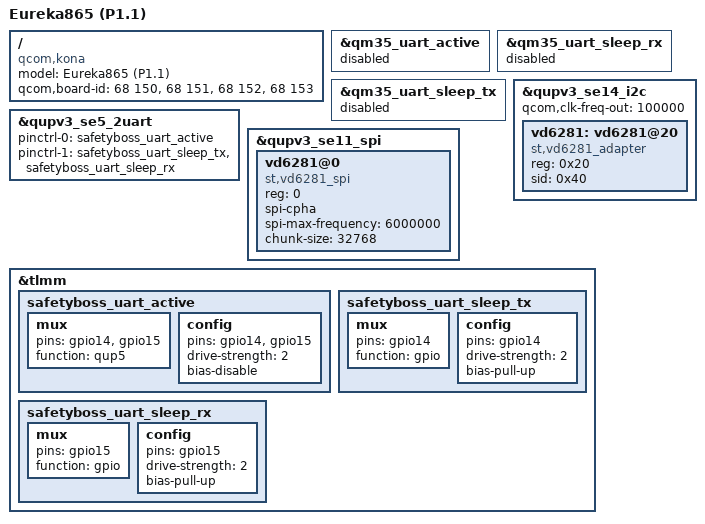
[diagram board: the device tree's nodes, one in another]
// SPDX-License-Identifier: GPL-2.0

/dts-v1/;
/plugin/;

#include "eureka865.dtsi"
#include "eureka865-p1.dtsi"

/ {
	model = "Eureka865 (P1.1)";
	compatible = "qcom,kona";
	qcom,board-id = <68 150>, <68 151>, <68 152>, <68 153>;
};

&qm35_uart_active {
	status = "disabled";
};

&qm35_uart_sleep_rx {
	status = "disabled";
};

&qm35_uart_sleep_tx {
	status = "disabled";
};

&qupv3_se5_2uart {
	pinctrl-0 = <&safetyboss_uart_active>;
	pinctrl-1 = <&safetyboss_uart_sleep_tx &safetyboss_uart_sleep_rx>;
};

&qupv3_se11_spi {
	status = "ok";
	vd6281@0 {
		compatible = "st,vd6281_spi";
		reg = <0>;
		spi-cpha;
		spi-max-frequency = <6000000>;
		chunk-size = <32768>;
		status = "ok";
	};
};

&qupv3_se14_i2c {
	status = "ok";
	qcom,clk-freq-out = <100000>;

	vd6281: vd6281@20 {
		compatible = "st,vd6281_adapter";
		reg = <0x20>;
		sid = <0x40>;
		status = "ok";
	};
};

&tlmm {
	safetyboss_uart_active: safetyboss_uart_active {
		mux {
			pins = "gpio14", "gpio15";
			function = "qup5";
		};
		config {
			pins = "gpio14", "gpio15";
			drive-strength = <2>;
			bias-disable;
		};
	};

	safetyboss_uart_sleep_tx: safetyboss_uart_sleep_tx {
		mux {
			pins = "gpio14";
			function = "gpio";
		};
		config {
			pins = "gpio14";
			drive-strength = <2>;
			bias-pull-up;
		};
	};

	safetyboss_uart_sleep_rx: safetyboss_uart_sleep_rx {
		mux {
			pins = "gpio15";
			function = "gpio";
		};
		config {
			pins = "gpio15";
			drive-strength = <2>;
			bias-pull-up;
		};
	};
};
